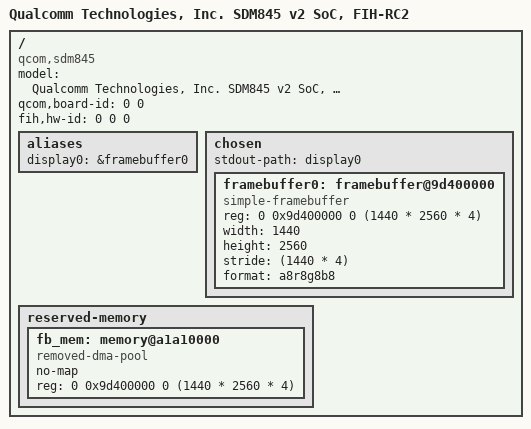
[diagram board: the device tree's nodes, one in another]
/* Copyright (c) 2017, The Linux Foundation. All rights reserved.
 *
 * This program is free software; you can redistribute it and/or modify
 * it under the terms of the GNU General Public License version 2 and
 * only version 2 as published by the Free Software Foundation.
 *
 * This program is distributed in the hope that it will be useful,
 * but WITHOUT ANY WARRANTY; without even the implied warranty of
 * MERCHANTABILITY or FITNESS FOR A PARTICULAR PURPOSE.  See the
 * GNU General Public License for more details.
 */

/dts-v1/;

#include "../../qcom/sdm845-v2.dtsi"
#include "sdm845-v2_rc2.dtsi"

/ {
	model = "Qualcomm Technologies, Inc. SDM845 v2 SoC, FIH-RC2";
	compatible = "qcom,sdm845";
	qcom,board-id = <0 0>;
	fih,hw-id = <0 0 0>;

	aliases {
		display0 = &framebuffer0;
	};

	chosen {
		#address-cells = <2>;
		#size-cells = <2>;
		ranges;
		stdout-path = "display0";

		/*
		 * HACK: Use framebuffer setup by the bootloader for simplefb.
		 * https://wiki.postmarketos.org/wiki/SDM845_Mainlining#Creating_a_framebuffer
		 */
		framebuffer0: framebuffer@9d400000 {
			compatible = "simple-framebuffer";
			reg = <0 0x9d400000 0 (1440 * 2560 * 4)>;
			width = <1440>;
			height = <2560>;
			stride = <(1440 * 4)>;
			format = "a8r8g8b8";
			status = "okay";
		};
	};

	reserved-memory {
		fb_mem: memory@a1a10000 {
			compatible = "removed-dma-pool";
			no-map;
			reg = <0 0x9d400000 0 (1440 * 2560 * 4)>;
		};
	};
};
